# R40 register map
Vendor: Allwinner; Series: R40; File version: 0.1
CPU: CA7 0, little endian, MPU, FPU, double-precision FPU, 0 interrupt priority bits
Registers are 32-bit, read-write, reset 0x0 unless marked. A register's access mark holds for its fields unless they carry their own. Offsets are from the block's base; [hi:lo] are bit positions.

## PS2-0
Base 0x01C2A000
Same registers: PS2-1 0x01C2A400
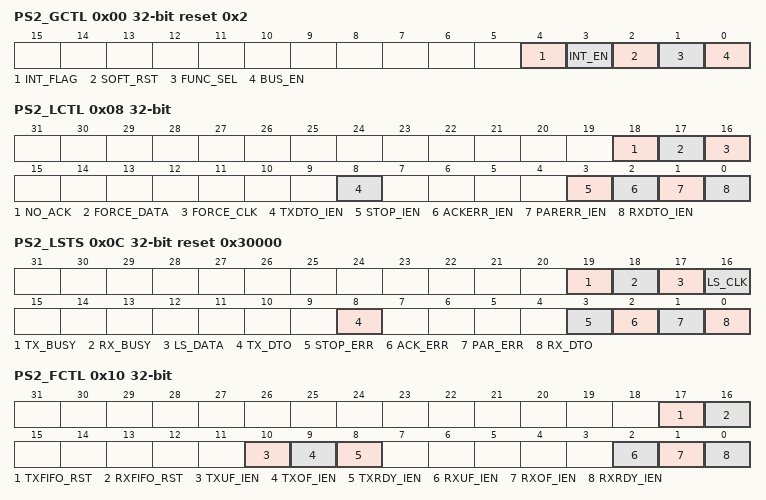
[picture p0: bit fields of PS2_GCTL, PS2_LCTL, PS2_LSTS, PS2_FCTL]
0x00 PS2_GCTL reset 0x2 — PS2 Module Global Control Register
  [4] INT_FLAG ro — Interrupt Flag The interrupt flag is set when any bit in FIFO Status and the corresponding enable bit in FIFO Control are set at the same time. This interrupt flag is also set when error flag bit in line status register ( ) is set at the same time. Note: This bit is just a status flag, it can not be cleared directly, it can be cleared by clearing the status bits in FIFO Status Register.
  [3] INT_EN — Interrupt Enable 0: The interrupt signal is always low 1: The interrupt signal will be high when is set
    0=always_low (The interrupt signal is always low); 1=interrupt_signal_will_be (The interrupt signal will be high when is set)
  [2] SOFT_RST — Soft Reset Setting this bit will reset transmitter and receiver of PS2 Module, and the status of transmitter and receiver will revert to the default state, but not affect any control bits in register, and data in TXFIFO/RXFIFO. This bit will be cleared by hardware after reset is completed.
  [1] FUNC_SEL — Master/Device Function Select 0: Device Function, connect to Computer 1: Master Function, connect to PS2 Keyboard or Mouse
    0=Device Function, connect to Computer; 1=Master Function, connect to PS2 Keyboard or Mouse
  [0] BUS_EN — PS2 Bus Enable 0: Ignore PS2 Bus Input 1: Response to PS2 Bus Input
    0=Ignore PS2 Bus Input; 1=Response to PS2 Bus Input
0x04 PS2_DATA — PS2 Module Data Register
  [7:0] PS2_DATA — When write, data will be written into TXFIFO, and will be transmited on to the PS2 Bus. When read, data is read out from RXFIFO, and it is received from PS2 Bus. Note: (1) After TXFIFO is full, writing does not affect anything except the overflow flag of TXFIFO in FIFO Status Register. (2) After RXFIFO is empty, reading has no effect on anything except the underflow flag of RXFIFO in FIFO Status Register.
0x08 PS2_LCTL — PS2 Module Line Control Register
  [18] NO_ACK — ACK Control 0: In Host function mode, must check ACK after transmitted data; in Device function mode, must send ACK after received data from Host. 1: In Host function mode, don`t check ACK after transmitted data; in Device function mode, don`t send ACK after received data from Host.
    0=comma__must_check (In Host function mode, must check ACK after transmitted data; in Device function mode, must send ACK after received data from Host.); 1=comma__don`t (In Host function mode, don`t check ACK after transmitted data; in Device function mode, don`t send ACK after received data from Host.)
  [17] FORCE_DATA — Force Data to Low 0: Data Line works in Normal Mode 1: Data Line is forced to Low
    0=Data Line works in Normal Mode; 1=forced (Data Line is forced to Low)
  [16] FORCE_CLK — Force Clock to Low 0: Clock Line works in Normal Mode 1: Clock Line is forced to Low
    0=Clock Line works in Normal Mode; 1=forced (Clock Line is forced to Low)
  [8] TXDTO_IEN — TX Data Timeout Interrupt Enable
  [3] STOP_IEN — Stop Error Interrupt Enable
  [2] ACKERR_IEN — Acknowledge Error Interrupt Enable
  [1] PARERR_IEN — Parity Error Interrupt Enable
  [0] RXDTO_IEN — RX Data Timeout Interrupt Enable
0x0C PS2_LSTS reset 0x30000 — PS2 Module Line Status Register
  [19] TX_BUSY write-1-clears — Transmit Busy 0: PS2 Module Transmit Engine is Idle. 1: PS2 Module is currently sending data. Note: This bit can be cleared by writing `1`. Writing `0` has no effect.
    0=PS2 Module Transmit Engine is Idle; 1=currently (PS2 Module is currently sending data. Note: This bit can be cleared by writing `1`. Writing `0` has no effect.)
  [18] RX_BUSY write-1-clears — Receive Busy 0: PS2 Module Receive Engine is Idle. 1: PS2 Module is currently receiving data. Note: This bit can be cleared by writing `1`. Writing `0` has no effect.
    0=PS2 Module Receive Engine is Idle; 1=currently (PS2 Module is currently receiving data. Note: This bit can be cleared by writing `1`. Writing `0` has no effect.)
  [17] LS_DATA ro — Line State of DATA. Invalid before BUS_EN set.
  [16] LS_CLK ro — Line State of CLOCK. Invalid before BUS_EN set.
  [8] TX_DTO write-1-clears — Transmit Data Timeout Timers include: Tc2c<15ms (Host pull low Clock to Device drive Clock) Tdata<2ms (Time for packet to send) Tckl+Tckh<100us(one cycle time, as host) Note: This bit can be cleared by writing `1`.Writing `0` has no effect.
  [3] STOP_ERR write-1-clears — Stop Bit Error 0: No Error 1: Stop Error This bit can be cleared by writing `1`.Writing `0` has no effect.
    0=No_Error; 1=Stop Error This bit can be cleared by writing `1`.Writing `0` has no effect
  [2] ACK_ERR write-1-clears — Acknowledge Error 0: ACK is received after data transmitted. 1: ACK is not received after data transmitted. Note: (1) Only for Master Function; (2) This bit can be cleared by writing `1`. Writing `0` has no effect.
    0=received (ACK is received after data transmitted.); 1=not_received (ACK is not received after data transmitted. Note: (1) Only for Master Function; (2) This bit can be cleared by writing `1`. Writing `0` has no effect.)
  [1] PAR_ERR write-1-clears — Parity Error 0: No Error 1: Parity Error Note: This bit can be cleared by writing `1`. Writing `0` has no effect.
    0=No_Error; 1=Parity Error Note: This bit can be cleared by writing `1`. Writing `0` has no effect.
  [0] RX_DTO — Receive Data Timeout Timers include: Trsp<20ms(time from the host releases the Clock line to device sends corresponding response) Tckl+Tckh<100us(one cycle time, as host) Note: This bit can be cleared by writing `1`.Writing `0` has no effect.
0x10 PS2_FCTL — PS2 Module FIFO Control Register
  [17] TXFIFO_RST — TXFIFO Reset After this bit is set, data in TXFIFO is flushed, and the pointer of TXFIFO is reset. Note: This bit is cleared automatically after TXFIFO is reset, and writing `0` has no effect.
  [16] RXFIFO_RST — RXFIFO Reset After this bit is set, data in RXFIFO is flushed, and the pointer of RXFIFO is reset. Note: This bit is cleared automatically after RXFIFO is reset, and writing `0` has no effect.
  [10] TXUF_IEN — TXFIFO Underflow Interrupt Enable
  [9] TXOF_IEN — TXFIFO Overflow Interrupt Enable
  [8] TXRDY_IEN — TXFIFO Ready Interrupt Enable
  [2] RXUF_IEN — RXFIFO Underflow Interrupt Enable
  [1] RXOF_IEN — RXFIFO Overflow Interrupt Enable
  [0] RXRDY_IEN — RXFIFO Ready Interrupt Enable
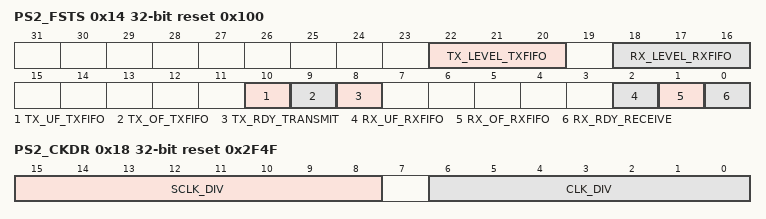
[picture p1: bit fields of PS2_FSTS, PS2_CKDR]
0x14 PS2_FSTS reset 0x100 — PS2 Module FIFO Status Register
  [22:20] TX_LEVEL_TXFIFO ro — TX_LEVEL TXFIFO Level The number of 8bit data, which is transmitted to PS2 Bus, in the TXFIFO. The value must be in the range of 0 to 4.
  [18:16] RX_LEVEL_RXFIFO ro — RX_LEVEL RXFIFO Level The number of 8bit data, which is received from PS2 bus, in the RXFIFO. The value must be in the range of 0 to 4.
  [10] TX_UF_TXFIFO write-1-clears — TX_UF TXFIFO Underflow When this bit is set, TXFIFO is underflow, and it means that the TXFIFO is read by transmit engine after empty. This bit is just a flag of illegal operation, which should not affect any state of TXFIFO. Note: This bit can be cleared by writing `1`. Writing `0` has no effect.
  [9] TX_OF_TXFIFO write-1-clears — TX_OF TXFIFO Overflow When this bit is set, TXFIFO is overflow, and it means that the TXFIFO is written by CPU after TXFIFO is full. This bit is just a flag of illegal operation, which should not affect any state of TXFIFO. Note: This bit can be cleared by writing `1`.Writing `0` has no effect.
  [8] TX_RDY_TRANSMIT write-1-clears — TX_RDY Transmit Ready 0: TXFIFO is full 1: TXFIFO is not full. Note: This bit can be cleared by writing `1`, writing `0` has no effect.
    0=full (TXFIFO is full); 1=not_full (TXFIFO is not full. Note: This bit can be cleared by writing `1`, writing `0` has no effect.)
  [2] RX_UF_RXFIFO write-1-clears — RX_UF RXFIFO Underflow When this bit is set, RXFIFO is underflow, and it means that the RXFIFO is read by CPU after empty. This bit is just a flag of illegal operation, which should not affect any state of RXFIFO. Note: This bit can be cleared by writing `1`. Writing `0` has no effect.
  [1] RX_OF_RXFIFO write-1-clears — RX_OF RXFIFO Overflow When this bit is set, RXFIFO is overflow, and it means that the RXFIFO is written by received engine after RXFIFO is full. This bit is just a flag of illegal operation, which should not affect any state of RXFIFO. Note: This bit can be cleared by writing `1`. Writing `0` has no effect.
  [0] RX_RDY_RECEIVE write-1-clears — RX_RDY Receive Ready 0: RXFIFO is empty 1:RXFIFO is not empty, there are at least one byte data, which is received from PS2 bus, in the RXFIFO. Note: This bit can be cleared by writing `1`.Writing `0` has no effect.
    0=RXFIFO (RXFIFO is empty 1:RXFIFO is not empty, there are at least one byte data, which is received from PS2 bus, in the RXFIFO. Note: This bit can be cleared by writing `1`.Writing `0` has no effect.)
0x18 PS2_CKDR reset 0x2F4F — PS2 Module Clock Divider Register
  [15:8] SCLK_DIV — Sample Clock Divider Factor (SCDF) Sample Clock is a 1MHz clock for internal timing control. SCDF = APB_CLK/SAMPLE_CLK - 1 Frequency of sample clock is constant, and so, frequency of APB_CLK must be in the range of 1MHz to 256MHz.
  [6:0] CLK_DIV — PS2 Clock Divider Factor (PCDF) PCDF = SAMPLE_CLK /PS2_CLK - 1 = 1MHz/PS2_CLK - 1 The frequency of PS2_CLK must be in the range of 10KHz to 16.7KHz. Note: This factor is used in device mode only.
